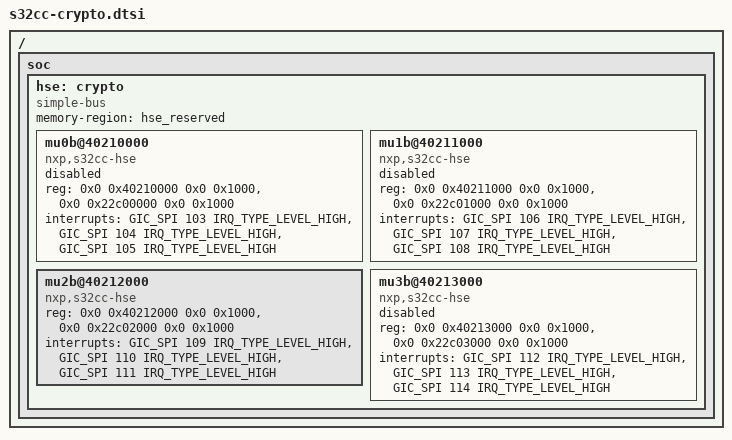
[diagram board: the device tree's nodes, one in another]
// SPDX-License-Identifier: (GPL-2.0+ OR BSD-3-Clause)
/*
 * Copyright 2022, 2024 NXP
 */

#include <dt-bindings/interrupt-controller/arm-gic.h>

/ {
	soc {
		hse: crypto {
			compatible = "simple-bus";
			#address-cells = <2>;
			#size-cells = <2>;
			#interrupt-cells = <3>;
			memory-region = <&hse_reserved>;
			ranges;

			mu0b@40210000 {
				compatible = "nxp,s32cc-hse";
				reg = <0x0 0x40210000 0x0 0x1000>,
				      <0x0 0x22c00000 0x0 0x1000>;
				reg-names = "hse-regs",
					    "hse-desc";
				interrupts = <GIC_SPI 103 IRQ_TYPE_LEVEL_HIGH>, /* GIC 135 */
					     <GIC_SPI 104 IRQ_TYPE_LEVEL_HIGH>, /* GIC 136 */
					     <GIC_SPI 105 IRQ_TYPE_LEVEL_HIGH>; /* GIC 137 */
				interrupt-names = "hse-ack",
						  "hse-rx",
						  "hse-err";
				status = "disabled";
			};

			mu1b@40211000 {
				compatible = "nxp,s32cc-hse";
				reg = <0x0 0x40211000 0x0 0x1000>,
				      <0x0 0x22c01000 0x0 0x1000>;
				reg-names = "hse-regs",
					    "hse-desc";
				interrupts = <GIC_SPI 106 IRQ_TYPE_LEVEL_HIGH>, /* GIC 138 */
					     <GIC_SPI 107 IRQ_TYPE_LEVEL_HIGH>, /* GIC 139 */
					     <GIC_SPI 108 IRQ_TYPE_LEVEL_HIGH>; /* GIC 140 */
				interrupt-names = "hse-ack",
						  "hse-rx",
						  "hse-err";
				status = "disabled";
			};

			mu2b@40212000 {
				compatible = "nxp,s32cc-hse";
				reg = <0x0 0x40212000 0x0 0x1000>,
				      <0x0 0x22c02000 0x0 0x1000>;
				reg-names = "hse-regs",
					    "hse-desc";
				interrupts = <GIC_SPI 109 IRQ_TYPE_LEVEL_HIGH>, /* GIC 141 */
					     <GIC_SPI 110 IRQ_TYPE_LEVEL_HIGH>, /* GIC 142 */
					     <GIC_SPI 111 IRQ_TYPE_LEVEL_HIGH>; /* GIC 143 */
				interrupt-names = "hse-ack",
						  "hse-rx",
						  "hse-err";
				status = "okay";
			};

			mu3b@40213000 {
				compatible = "nxp,s32cc-hse";
				reg = <0x0 0x40213000 0x0 0x1000>,
				      <0x0 0x22c03000 0x0 0x1000>;
				reg-names = "hse-regs",
					    "hse-desc";
				interrupts = <GIC_SPI 112 IRQ_TYPE_LEVEL_HIGH>, /* GIC 144 */
					     <GIC_SPI 113 IRQ_TYPE_LEVEL_HIGH>, /* GIC 145 */
					     <GIC_SPI 114 IRQ_TYPE_LEVEL_HIGH>; /* GIC 146 */
				interrupt-names = "hse-ack",
						  "hse-rx",
						  "hse-err";
				status = "disabled";
			};
		};
	};
};
